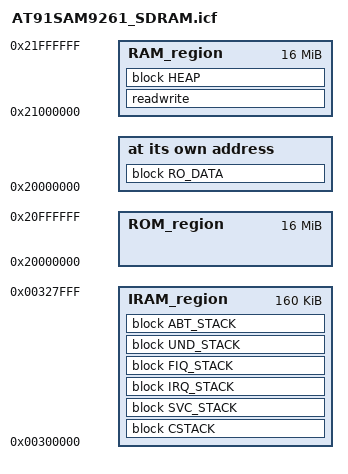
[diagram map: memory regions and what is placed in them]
/*###ICF### Section handled by ICF editor, don't touch! ****/
/*-Editor annotation file-*/
/* IcfEditorFile="$TOOLKIT_DIR$\config\ide\IcfEditor\a_v1_0.xml" */
/*-Specials-*/
define symbol __ICFEDIT_intvec_start__ = 0x20000000;       // Located at start of SDRAM
/*-Memory Regions-*/
define symbol __ICFEDIT_region_ROM_start__ = 0x20000000;   // Program runs in SDRAM
define symbol __ICFEDIT_region_ROM_end__   = 0x20FFFFFF;
define symbol __ICFEDIT_region_RAM_start__ = 0x21000000;
define symbol __ICFEDIT_region_RAM_end__   = 0x21FFFFFF;
/*-Sizes-*/
define symbol __ICFEDIT_size_cstack__   = 0x800;
define symbol __ICFEDIT_size_svcstack__ = 0x0;
define symbol __ICFEDIT_size_irqstack__ = 0x200;     // (4 * (4 * 8)) = Nesting level * (4 * 8) bytes. Total size has to be a multiple of 8 bytes !
define symbol __ICFEDIT_size_fiqstack__ = 0x40;     // Not used in most applications, if no FIQ is used you can reduce it to 0.
define symbol __ICFEDIT_size_undstack__ = 0x0;
define symbol __ICFEDIT_size_abtstack__ = 0x0;
define symbol __ICFEDIT_size_heap__     = 0x80000;
/**** End of ICF editor section. ###ICF###*/

define symbol __ICFEDIT_region_IRAM_start__ = 0x00300000;  //
define symbol __ICFEDIT_region_IRAM_end__   = 0x00327FFF;  // Size of internal SRAM1 is 160 KBytes

define memory mem with size = 4G;
define region ROM_region   = mem:[from __ICFEDIT_region_ROM_start__   to __ICFEDIT_region_ROM_end__];
define region RAM_region   = mem:[from __ICFEDIT_region_RAM_start__   to __ICFEDIT_region_RAM_end__];
define region IRAM_region  = mem:[from __ICFEDIT_region_IRAM_start__  to __ICFEDIT_region_IRAM_end__];

define block CSTACK    with alignment = 8, size = __ICFEDIT_size_cstack__   { };
define block SVC_STACK with alignment = 8, size = __ICFEDIT_size_svcstack__ { };
define block IRQ_STACK with alignment = 8, size = __ICFEDIT_size_irqstack__ { };
define block FIQ_STACK with alignment = 8, size = __ICFEDIT_size_fiqstack__ { };
define block UND_STACK with alignment = 8, size = __ICFEDIT_size_undstack__ { };
define block ABT_STACK with alignment = 8, size = __ICFEDIT_size_abtstack__ { };
define block HEAP      with alignment = 8, size = __ICFEDIT_size_heap__     { };

/*initialize by copy { readwrite };*/
/*compression. Consider using "initialize by copy with packing = zeros" (or none) instead.*/
/*initialize by copy with packing = zeros;*/

do not initialize  { section .noinit };

define block RO_DATA { first readonly section .intvec, readonly };

place at address mem:__ICFEDIT_intvec_start__  { block RO_DATA };

place in RAM_region  { readwrite,
                       block HEAP };

place in IRAM_region { block CSTACK, block SVC_STACK, block IRQ_STACK, block FIQ_STACK,
                       block UND_STACK, block ABT_STACK };
